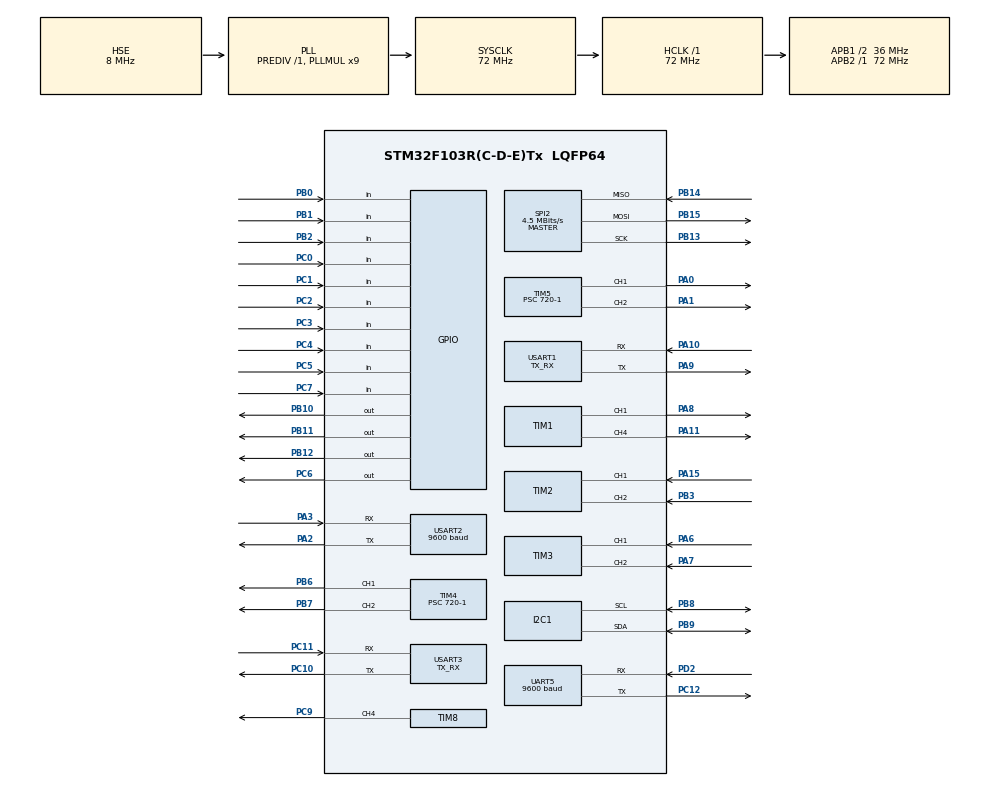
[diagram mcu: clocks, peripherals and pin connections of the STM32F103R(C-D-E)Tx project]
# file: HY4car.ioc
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I2C1.I2C_Mode=I2C_Fast
Mcu.Family=STM32F1
Mcu.Name=STM32F103R(C-D-E)Tx
Mcu.Package=LQFP64
NVIC.I2C1_EV_IRQn=true\:1\:0\:true\:false\:true\:true\:true\:true
NVIC.PriorityGroup=NVIC_PRIORITYGROUP_4
NVIC.TIM2_IRQn=true\:4\:0\:true\:false\:true\:true\:true\:true
NVIC.TIM3_IRQn=true\:4\:0\:true\:false\:true\:true\:true\:true
NVIC.TIM6_IRQn=true\:5\:0\:true\:false\:true\:true\:true\:true
NVIC.USART1_IRQn=true\:0\:0\:false\:false\:true\:true\:true\:true
NVIC.USART2_IRQn=true\:2\:0\:true\:false\:true\:true\:true\:true
PA0-WKUP.Signal=S_TIM5_CH1
PA1.Signal=S_TIM5_CH2
PA10.Mode=Asynchronous
PA10.Signal=USART1_RX
PA11.Signal=S_TIM1_CH4
PA13.Mode=Serial_Wire
PA13.Signal=SYS_JTMS-SWDIO
PA14.Mode=Serial_Wire
PA14.Signal=SYS_JTCK-SWCLK
PA15.Signal=S_TIM2_CH1_ETR
PA2.Mode=Asynchronous
PA2.Signal=USART2_TX
PA3.Mode=Asynchronous
PA3.Signal=USART2_RX
PA6.Signal=S_TIM3_CH1
PA7.Signal=S_TIM3_CH2
PA8.Signal=S_TIM1_CH1
PA9.Mode=Asynchronous
PA9.Signal=USART1_TX
PB0.Signal=GPIO_Input
PB1.Signal=GPIO_Input
PB10.Signal=GPIO_Output
PB11.GPIO_ModeDefaultOutputPP=GPIO_MODE_OUTPUT_OD
PB11.GPIO_PuPd=GPIO_PULLUP
PB11.GPIO_Speed=GPIO_SPEED_FREQ_HIGH
PB11.Signal=GPIO_Output
PB12.Signal=GPIO_Output
PB13.Mode=Full_Duplex_Master
PB13.Signal=SPI2_SCK
PB14.Mode=Full_Duplex_Master
PB14.Signal=SPI2_MISO
PB15.Mode=Full_Duplex_Master
PB15.Signal=SPI2_MOSI
PB2.Signal=GPIO_Input
PB3.Signal=S_TIM2_CH2
PB6.Signal=S_TIM4_CH1
PB7.Signal=S_TIM4_CH2
PB8.Mode=I2C
PB8.Signal=I2C1_SCL
PB9.Mode=I2C
PB9.Signal=I2C1_SDA
PC0.Signal=GPIO_Input
PC1.Signal=GPIO_Input
PC10.Mode=Asynchronous
PC10.Signal=USART3_TX
PC11.Mode=Asynchronous
PC11.Signal=USART3_RX
PC12.Mode=Asynchronous
PC12.Signal=UART5_TX
PC14-OSC32_IN.Mode=LSE-External-Oscillator
PC14-OSC32_IN.Signal=RCC_OSC32_IN
PC15-OSC32_OUT.Mode=LSE-External-Oscillator
PC15-OSC32_OUT.Signal=RCC_OSC32_OUT
PC2.Signal=GPIO_Input
PC3.Signal=GPIO_Input
PC4.Signal=GPIO_Input
PC5.Signal=GPIO_Input
PC6.GPIO_Speed=GPIO_SPEED_FREQ_HIGH
PC6.Signal=GPIO_Output
PC7.GPIO_PuPd=GPIO_PULLUP
PC7.Signal=GPIO_Input
PC9.Signal=S_TIM8_CH4
PD0-OSC_IN.Mode=HSE-External-Oscillator
PD0-OSC_IN.Signal=RCC_OSC_IN
PD1-OSC_OUT.Mode=HSE-External-Oscillator
PD1-OSC_OUT.Signal=RCC_OSC_OUT
PD2.Mode=Asynchronous
PD2.Signal=UART5_RX
ProjectManager.HeapSize=0x200
ProjectManager.StackSize=0x400
ProjectManager.TargetToolchain=MDK-ARM V5
RCC.AHBFreq_Value=72000000
RCC.APB1CLKDivider=RCC_HCLK_DIV2
RCC.APB1Freq_Value=36000000
RCC.APB1TimFreq_Value=72000000
RCC.APB2Freq_Value=72000000
RCC.APB2TimFreq_Value=72000000
RCC.HCLKFreq_Value=72000000
RCC.PLLMUL=RCC_PLL_MUL9
RCC.PLLSourceVirtual=RCC_PLLSOURCE_HSE
RCC.SYSCLKFreq_VALUE=72000000
RCC.SYSCLKSource=RCC_SYSCLKSOURCE_PLLCLK
RCC.USBFreq_Value=72000000
SH.S_TIM1_CH1.0=TIM1_CH1,PWM Generation1 CH1
SH.S_TIM1_CH4.0=TIM1_CH4,PWM Generation4 CH4
SH.S_TIM2_CH1_ETR.0=TIM2_CH1,Encoder_Interface
SH.S_TIM2_CH2.0=TIM2_CH2,Encoder_Interface
SH.S_TIM3_CH1.0=TIM3_CH1,Encoder_Interface
SH.S_TIM3_CH2.0=TIM3_CH2,Encoder_Interface
SH.S_TIM4_CH1.0=TIM4_CH1,PWM Generation1 CH1
SH.S_TIM4_CH2.0=TIM4_CH2,PWM Generation2 CH2
SH.S_TIM5_CH1.0=TIM5_CH1,PWM Generation1 CH1
SH.S_TIM5_CH2.0=TIM5_CH2,PWM Generation2 CH2
SH.S_TIM8_CH4.0=TIM8_CH4,PWM Generation4 CH4
SPI2.BaudRatePrescaler=SPI_BAUDRATEPRESCALER_8
SPI2.CalculateBaudRate=4.5 MBits/s
SPI2.Direction=SPI_DIRECTION_2LINES
SPI2.Mode=SPI_MODE_MASTER
SPI2.VirtualType=VM_MASTER
TIM1.Channel-PWM\ Generation1\ CH1=TIM_CHANNEL_1
TIM1.Channel-PWM\ Generation4\ CH4=TIM_CHANNEL_4
TIM2.EncoderMode=TIM_ENCODERMODE_TI12
TIM3.EncoderMode=TIM_ENCODERMODE_TI12
TIM4.AutoReloadPreload=TIM_AUTORELOAD_PRELOAD_ENABLE
TIM4.Channel-PWM\ Generation1\ CH1=TIM_CHANNEL_1
TIM4.Channel-PWM\ Generation2\ CH2=TIM_CHANNEL_2
TIM4.Period=1000-1
TIM4.Prescaler=720-1
TIM5.AutoReloadPreload=TIM_AUTORELOAD_PRELOAD_ENABLE
TIM5.Channel-PWM\ Generation1\ CH1=TIM_CHANNEL_1
TIM5.Channel-PWM\ Generation2\ CH2=TIM_CHANNEL_2
TIM5.Period=1000-1
TIM5.Prescaler=720-1
TIM6.AutoReloadPreload=TIM_AUTORELOAD_PRELOAD_DISABLE
TIM6.Period=20000-1
TIM6.Prescaler=72-1
TIM8.Channel-PWM\ Generation4\ CH4=TIM_CHANNEL_4
UART5.BaudRate=9600
UART5.VirtualMode=Asynchronous
USART1.Mode=MODE_TX_RX
USART1.VirtualMode=VM_ASYNC
USART2.BaudRate=9600
USART2.VirtualMode=VM_ASYNC
USART3.Mode=MODE_TX_RX
USART3.VirtualMode=VM_ASYNC
VP_TIM1_VS_ClockSourceINT.Mode=Internal
VP_TIM4_VS_ClockSourceINT.Mode=Internal
VP_TIM5_VS_ClockSourceINT.Mode=Internal
VP_TIM6_VS_ClockSourceINT.Mode=Enable_Timer
VP_TIM8_VS_ClockSourceINT.Mode=Internal
board=custom

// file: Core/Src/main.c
// /* USER CODE BEGIN Header */
// /**
//   ******************************************************************************
//   * @file           : main.c
//   * @brief          : Main program body
//   ******************************************************************************
//   * @attention
//   *
//   * Copyright (c) 2024 STMicroelectronics.
//   * All rights reserved.
//   *
//   * This software is licensed under terms that can be found in the LICENSE file
//   * in the root directory of this software component.
//   * If no LICENSE file comes with this software, it is provided AS-IS.
//   *
//   ******************************************************************************
//   */
// /* USER CODE END Header */
// /* Includes ------------------------------------------------------------------*/
#include "main.h"
#include "i2c.h"
#include "spi.h"
#include "tim.h"
#include "usart.h"
#include "gpio.h"

// /* Private includes ----------------------------------------------------------*/
// /* USER CODE BEGIN Includes */
#include "imu901.h"
#include "button.h"
#include "astar.h"
#include "translate_route_cmd.h"
#include "plan.h"
#include "startup_strategy.h"
// /* USER CODE END Includes */
// /* Private typedef -----------------------------------------------------------*/
// /* USER CODE BEGIN PTD */
// /* USER CODE END PTD */
// /* Private define ------------------------------------------------------------*/
// /* USER CODE BEGIN PD */
// /* USER CODE END PD */
// /* Private macro -------------------------------------------------------------*/
// /* USER CODE BEGIN PM */
// /* USER CODE END PM */
// /* Private variables ---------------------------------------------------------*/
// /* USER CODE BEGIN PV */
// /* USER CODE END PV */
// /* Private function prototypes -----------------------------------------------*/
void SystemClock_Config(void);
// /* USER CODE BEGIN PFP */
// /* USER CODE END PFP */
// /* Private user code ---------------------------------------------------------*/
// /* USER CODE BEGIN 0 */
short x, y, z;
uint8_t res1 = 8;
/* USER CODE END 0 */
int main(void)
{
    /* USER CODE BEGIN 1 */
    //   float pitch, roll, yaw;

    //    short	aacx, aacy, aacz;
    //    char k[20] = "";
    //    char k1[20] = "";
    //    char s1[10] = "";
    //    uint8_t s[1] = "n";
    //   uint8_t seven_commend[4] = {0x4c, 0x01, 0x01, 0x00};
    uint8_t seven_commend[4] = {0x4c, 0x01, 0x05, 0x06};
    //    uint8_t tx_data[6];
    encoder_total_l = 0;
    encoder_total_r = 0;
    char k[20];
    /* USER CODE END 1 */

    /* MCU Configuration--------------------------------------------------------*/

    /* Reset of all peripherals, Initializes the Flash interface and the Systick. */
    HAL_Init();

    /* Configure the system clock */
    SystemClock_Config();

    /* Initialize all configured peripherals */
    MX_GPIO_Init();
    MX_SPI2_Init();
    MX_TIM2_Init();
    MX_TIM3_Init();
    MX_UART5_Init();
    MX_USART1_UART_Init();
    MX_USART2_UART_Init();
    MX_USART3_UART_Init();
    MX_TIM1_Init();
    MX_TIM4_Init();
    MX_TIM5_Init();
    MX_TIM8_Init();
    MX_TIM6_Init();
    MX_I2C1_Init();

    OLED_Init();
    imu901_init();

    OLED_Update();
    Encoder_Init();
    sevenway_init();
    Servos_Init();

    motor_pid_init();
    seven_line_pid_init();
    OLED_Clear();
    motor_speed_set(0, 0);

    GlobalLoc_Init();
    AStar_Init();
    TranslateRouteCmd_SetSpecialEdgeRules();

    static char test_s[100] = {'T', 'w', 'w', 'D', 'w', 'w', 'w', 'w', 'T', 'S'}; // 测试用
    // static char test_s[100] = {'d','t','D','T'}; //测试用
    static char te1[100] = {
        // manfen
        'O', '2', 'K', 'L', '2', 'R', 'w', '2', 'w', 'L', 'T', 'f', 'd',
        // 2方块
        'O', 't', 'b', 'D', 'R', '1', 'K', 'L', '1', 'O', 'L', 'L', '1', 'L', '1', 'K', 'L', 'L', '1', 'R', '1', 'O', 'w',
        // 2方块
        'L', 'L', 'w', '8', 'w', 'f', 'w', 'b', 'w',
        // 1 圆环
        'L', 'L', '1', 'R', '1', 'K', 'T', 'R', 'f', 'd', 'O', 'b',
        // 2 方块
        'b', 'w', 'L', 'L', 'w', '1', 'L', '2', 'L', '1', 'K', 'L', 'L', 'w', '1', 'R', '2', 'R', '1', 'O',
        'S', '\0'}; // 第一轮重启

    static char test_9[100] = {
        'O', 'K', 'T', '1', 'L', 'f', 'd', 'd', 'S'

    };

    static char test1[100] = {'T', 'w', 'w', 'T', 'w', 'w', 'D', 'w', 'w', 'D', 'w', 'w', 'S'};    /*·测试代码*/
    static char test_f_b[100] = {'1', 'w', 'w', 'f', 'w', 'w', 'b', 'w', 'w', 'w', 'w', 'w', 'S'}; /*·测试代码*/

    /*满分环*/ static char test2[100] = {'O', '2', 'K', 'L', '1', 'R', '2', 'w', 'L', '1', 'T', 'w', 'w', 'w', 'f', 'w', 'O', 'B', 'D', 'w', 'w', 'A', '1', 'L', '1', 'R', '7', 'S'};                                                                                                                                                                                  // 满分环990
    /*物块八分*/ static char test3[100] = {'O', '1', 'R', '1', 'L', '2', 'L', '1', 'R', '2', 'K', 'R', 'O', '3', 'A', 'w', '8', 'A', '1', 'R', '2', 'K', 'A', '2', 'L', '1', 'O', 'B', 'A', '2', 'L', '2', 'L', '2', 'K', 'A', '2', 'R', '2', 'R', '2', 'O', 'A', '3', 'R', '1', 'K', 'A', '1', 'R', '5', 'O', 'A', '1', 'L', '2', 'K', 'A', '2', 'R', '1', 'O', 'S'}; // 方块八分960
                                                                                                                                                                                                                                                                                                                                                                       // static char test4[100] = {'D','w','w','D','R','1','R','7','S'};
    /*完胜*/ static char test5[100] = {'O', '1', 'L', '2', 'R', '1', 'K', '2', 'L', 'T', 'w', 'f', 'w', 'O', 'B', 'D', 'w', 'A', '1', 'K', 'T', 'w', 'L', 'L', '1', 'w', 'f', 'w', 'O', 'S', 'B', 'D', 'w', 'A', '1', 'L', '1', 'R', '6', 'w', 'f', 'w', 'b', 'L', 'L', '1', 'R', '1', 'K', 't', 'w', 'R', 'f', 'w', 'O', 'B', 'w', 'd', 'w', 'w', 'A', '1', 'L', '2', 'K', 't', 'w', 'w', 'A', '2', 'R', '1', 'f', 'w', 'O', 'S'};
    startup_strategy_run();

    while (1)
    {
        delay_20ms(50);
    }
}

void SystemClock_Config(void)
{
    RCC_OscInitTypeDef RCC_OscInitStruct = {0};
    RCC_ClkInitTypeDef RCC_ClkInitStruct = {0};

    /** Initializes the RCC Oscillators according to the specified parameters
     * in the RCC_OscInitTypeDef structure.
     */
    RCC_OscInitStruct.OscillatorType = RCC_OSCILLATORTYPE_HSE;
    RCC_OscInitStruct.HSEState = RCC_HSE_ON;
    RCC_OscInitStruct.HSEPredivValue = RCC_HSE_PREDIV_DIV1;
    RCC_OscInitStruct.HSIState = RCC_HSI_ON;
    RCC_OscInitStruct.PLL.PLLState = RCC_PLL_ON;
    RCC_OscInitStruct.PLL.PLLSource = RCC_PLLSOURCE_HSE;
    RCC_OscInitStruct.PLL.PLLMUL = RCC_PLL_MUL9;
    if (HAL_RCC_OscConfig(&RCC_OscInitStruct) != HAL_OK)
    {
        Error_Handler();
    }

    /** Initializes the CPU, AHB and APB buses clocks
xz     */
    RCC_ClkInitStruct.ClockType = RCC_CLOCKTYPE_HCLK | RCC_CLOCKTYPE_SYSCLK | RCC_CLOCKTYPE_PCLK1 | RCC_CLOCKTYPE_PCLK2;
    RCC_ClkInitStruct.SYSCLKSource = RCC_SYSCLKSOURCE_PLLCLK;
    RCC_ClkInitStruct.AHBCLKDivider = RCC_SYSCLK_DIV1;
    RCC_ClkInitStruct.APB1CLKDivider = RCC_HCLK_DIV2;
    RCC_ClkInitStruct.APB2CLKDivider = RCC_HCLK_DIV1;

    if (HAL_RCC_ClockConfig(&RCC_ClkInitStruct, FLASH_LATENCY_2) != HAL_OK)
    {
        Error_Handler();
    }
}

void Error_Handler(void)
{
    __disable_irq();
    while (1)
    {
    }
}
